# allwinner_d1_unofficial register map
File version: 0.1
Registers are 32-bit, read-write, reset 0x0 unless marked. A register's access mark holds for its fields unless they carry their own. Offsets are from the block's base; [hi:lo] are bit positions; {n}, {i} and the like mark numbered series; 'fields as' and 'values as' point back to an identical list.

## CCU — Clock Controller Unit
Base 0x02001000
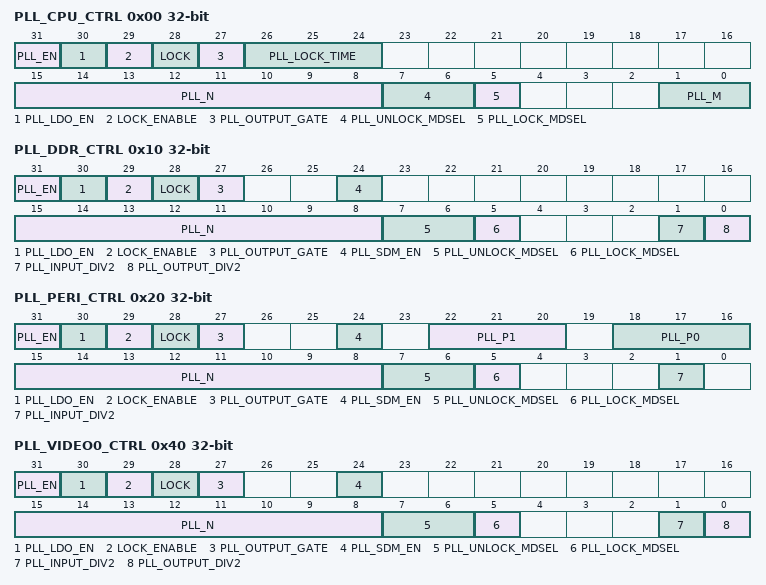
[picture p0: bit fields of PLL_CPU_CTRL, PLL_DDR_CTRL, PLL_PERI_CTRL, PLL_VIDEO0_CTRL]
0x00 PLL_CPU_CTRL — PLL_CPU Control Register
  [31] PLL_EN — PLL Enable
    0=disable; 1=enable
  [30] PLL_LDO_EN — LDO Enable
    0=disable; 1=enable
  [29] LOCK_ENABLE
    0=disable; 1=enable
  [28] LOCK ro — PLL Lock Status
    0=unlocked; 1=locked
  [27] PLL_OUTPUT_GATE — PLL Output Gating Enable
    0=disable; 1=enable
  [26:24] PLL_LOCK_TIME
  [15:8] PLL_N
  [7:6] PLL_UNLOCK_MDSEL — PLL Unlock Level
    0=CC_21_29; 1=CC_22_28; 0b1x=CC_20_30
  [5] PLL_LOCK_MDSEL — PLL Lock Level
    0=CC_24_26; 1=CC_23_27
  [1:0] PLL_M
0x10 PLL_DDR_CTRL — PLL_DDR Control Register
  [31] PLL_EN — PLL Enable
    0=disable; 1=enable
  [30] PLL_LDO_EN — LDO Enable
    0=disable; 1=enable
  [29] LOCK_ENABLE
    0=disable; 1=enable
  [28] LOCK ro — PLL Lock Status
    0=unlocked; 1=locked
  [27] PLL_OUTPUT_GATE — PLL Output Gating Enable
    0=disable; 1=enable
  [24] PLL_SDM_EN — PLL SDM Enable
    0=disable; 1=enable
  [15:8] PLL_N
  [7:6] PLL_UNLOCK_MDSEL — PLL Unlock Level
    0=CC_21_29; 1=CC_22_28; 0b1x=CC_20_30
  [5] PLL_LOCK_MDSEL — PLL Lock Level
    0=CC_24_26; 1=CC_23_27
  [1] PLL_INPUT_DIV2 — PLL Input Div M1
  [0] PLL_OUTPUT_DIV2 — PLL Output Div M0
0x20 PLL_PERI_CTRL — PLL_PERI Control Register
  [31] PLL_EN — PLL Enable
    0=disable; 1=enable
  [30] PLL_LDO_EN — LDO Enable
    0=disable; 1=enable
  [29] LOCK_ENABLE
    0=disable; 1=enable
  [28] LOCK ro — PLL Lock Status
    0=unlocked; 1=locked
  [27] PLL_OUTPUT_GATE — PLL Output Gating Enable
    0=disable; 1=enable
  [24] PLL_SDM_EN — PLL SDM Enable
    0=disable; 1=enable
  [22:20] PLL_P1 — PLL Output Div P1
  [18:16] PLL_P0 — PLL Output Div P0
  [15:8] PLL_N
  [7:6] PLL_UNLOCK_MDSEL — PLL Unlock Level
    0=CC_21_29; 1=CC_22_28; 0b1x=CC_20_30
  [5] PLL_LOCK_MDSEL — PLL Lock Level
    0=CC_24_26; 1=CC_23_27
  [1] PLL_INPUT_DIV2 — PLL Input Div M
0x40 PLL_VIDEO0_CTRL — PLL_VIDEO0 Control Register
  [31] PLL_EN — PLL Enable
    0=disable; 1=enable
  [30] PLL_LDO_EN — LDO Enable
    0=disable; 1=enable
  [29] LOCK_ENABLE
    0=disable; 1=enable
  [28] LOCK ro — PLL Lock Status
    0=unlocked; 1=locked
  [27] PLL_OUTPUT_GATE — PLL Output Gating Enable
    0=disable; 1=enable
  [24] PLL_SDM_EN — PLL SDM Enable
    0=disable; 1=enable
  [15:8] PLL_N
  [7:6] PLL_UNLOCK_MDSEL — PLL Unlock Level
    0=CC_21_29; 1=CC_22_28; 0b1x=CC_20_30
  [5] PLL_LOCK_MDSEL — PLL Lock Level
    0=CC_24_26; 1=CC_23_27
  [1] PLL_INPUT_DIV2 — PLL Input Div M
  [0] PLL_OUTPUT_DIV2 — PLL Output Div D
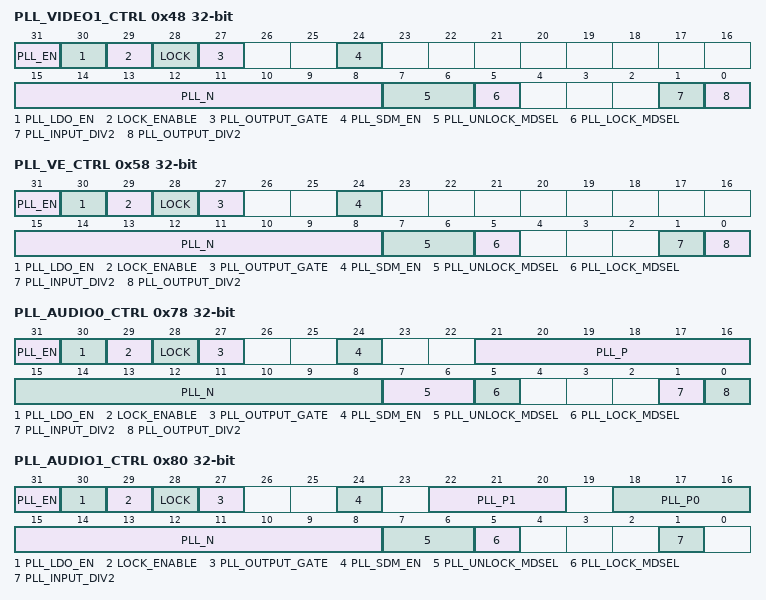
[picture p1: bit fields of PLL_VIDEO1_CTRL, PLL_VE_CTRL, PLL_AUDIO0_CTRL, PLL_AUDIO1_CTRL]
0x48 PLL_VIDEO1_CTRL — PLL_VIDEO1 Control Register
  fields as PLL_VIDEO0_CTRL
0x58 PLL_VE_CTRL — PLL_VE Control Register
  fields as PLL_DDR_CTRL
0x78 PLL_AUDIO0_CTRL — PLL_AUDIO0 Control Register
  [31] PLL_EN — PLL Enable
    0=disable; 1=enable
  [30] PLL_LDO_EN — LDO Enable
    0=disable; 1=enable
  [29] LOCK_ENABLE
    0=disable; 1=enable
  [28] LOCK ro — PLL Lock Status
    0=unlocked; 1=locked
  [27] PLL_OUTPUT_GATE — PLL Output Gating Enable
    0=disable; 1=enable
  [24] PLL_SDM_EN — PLL SDM Enable
    0=disable; 1=enable
  [21:16] PLL_P — PLL Post-div P
  [15:8] PLL_N
  [7:6] PLL_UNLOCK_MDSEL — PLL Unlock Level
    0=CC_21_29; 1=CC_22_28; 0b1x=CC_20_30
  [5] PLL_LOCK_MDSEL — PLL Lock Level
    0=CC_24_26; 1=CC_23_27
  [1] PLL_INPUT_DIV2 — PLL Input Div M1
  [0] PLL_OUTPUT_DIV2 — PLL Output Div M0
0x80 PLL_AUDIO1_CTRL — PLL_AUDIO1 Control Register
  fields as PLL_PERI_CTRL
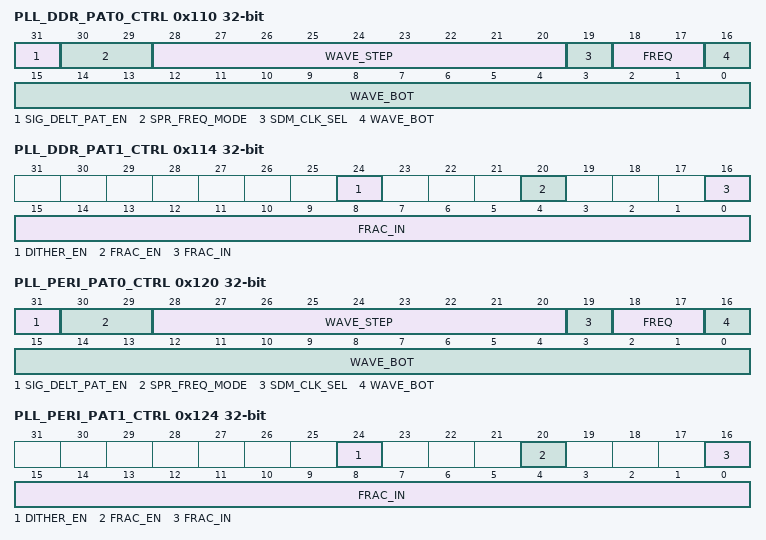
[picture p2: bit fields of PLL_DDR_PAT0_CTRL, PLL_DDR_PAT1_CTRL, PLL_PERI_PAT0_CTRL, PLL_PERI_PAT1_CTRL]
0x110 PLL_DDR_PAT0_CTRL — PLL_DDR Pattern0 Control Register
  [31] SIG_DELT_PAT_EN — Sigma-Delta Pattern Enable
  [30:29] SPR_FREQ_MODE — Spread Frequency Mode
    0=DC0; 1=DC1; 2=Triangular_1; 3=Triangular_n
  [28:20] WAVE_STEP
  [19] SDM_CLK_SEL — SDM Clock Select
    0=F_24_M; 1=F_12_M
  [18:17] FREQ — Frequency
    0=F_31_5_k; 1=F_32_k; 2=F_32_5_k; 3=F_33_k
  [16:0] WAVE_BOT — Wave Bottom
0x114 PLL_DDR_PAT1_CTRL — PLL_DDR Pattern1 Control Register
  [24] DITHER_EN — Dither Enable
  [20] FRAC_EN — Fraction Enable
  [16:0] FRAC_IN — Fraction In
0x120 PLL_PERI_PAT0_CTRL — PLL_PERI Pattern0 Control Register
  fields as PLL_DDR_PAT0_CTRL
0x124 PLL_PERI_PAT1_CTRL — PLL_PERI Pattern1 Control Register
  fields as PLL_DDR_PAT1_CTRL
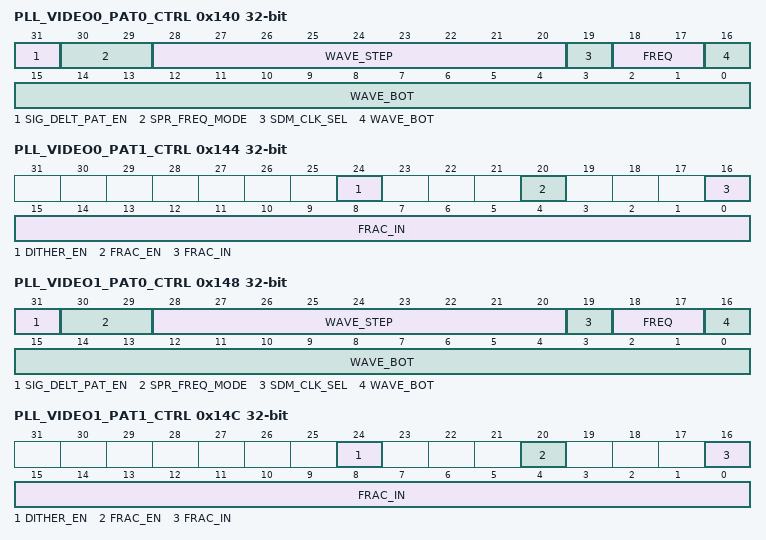
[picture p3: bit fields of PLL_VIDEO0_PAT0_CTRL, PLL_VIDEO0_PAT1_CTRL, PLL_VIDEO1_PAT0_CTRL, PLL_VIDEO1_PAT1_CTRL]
0x140 PLL_VIDEO0_PAT0_CTRL — PLL_VIDEO0 Pattern0 Control Register
  fields as PLL_DDR_PAT0_CTRL
0x144 PLL_VIDEO0_PAT1_CTRL — PLL_VIDEO0 Pattern1 Control Register
  fields as PLL_DDR_PAT1_CTRL
0x148 PLL_VIDEO1_PAT0_CTRL — PLL_VIDEO1 Pattern0 Control Register
  fields as PLL_DDR_PAT0_CTRL
0x14C PLL_VIDEO1_PAT1_CTRL — PLL_VIDEO1 Pattern1 Control Register
  fields as PLL_DDR_PAT1_CTRL
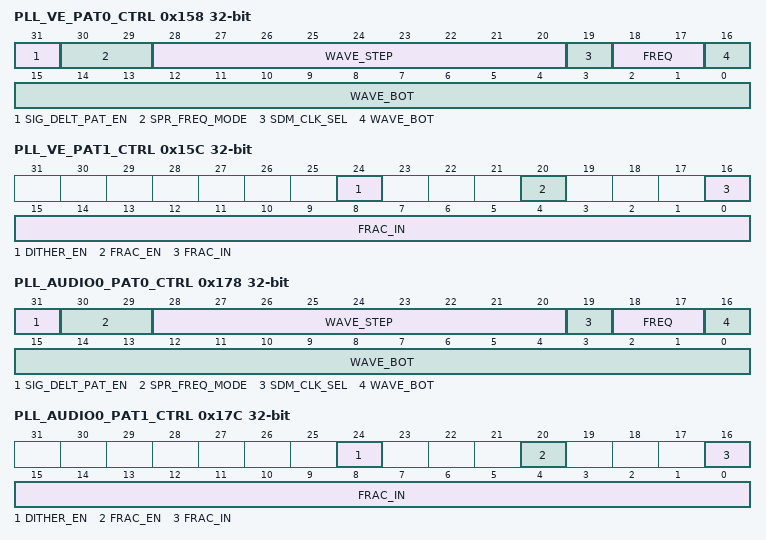
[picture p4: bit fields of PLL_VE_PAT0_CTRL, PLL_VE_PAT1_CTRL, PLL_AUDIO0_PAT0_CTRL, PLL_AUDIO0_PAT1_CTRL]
0x158 PLL_VE_PAT0_CTRL — PLL_VE Pattern0 Control Register
  fields as PLL_DDR_PAT0_CTRL
0x15C PLL_VE_PAT1_CTRL — PLL_VE Pattern1 Control Register
  fields as PLL_DDR_PAT1_CTRL
0x178 PLL_AUDIO0_PAT0_CTRL — PLL_AUDIO0 Pattern0 Control Register
  fields as PLL_DDR_PAT0_CTRL
0x17C PLL_AUDIO0_PAT1_CTRL — PLL_AUDIO0 Pattern1 Control Register
  fields as PLL_DDR_PAT1_CTRL
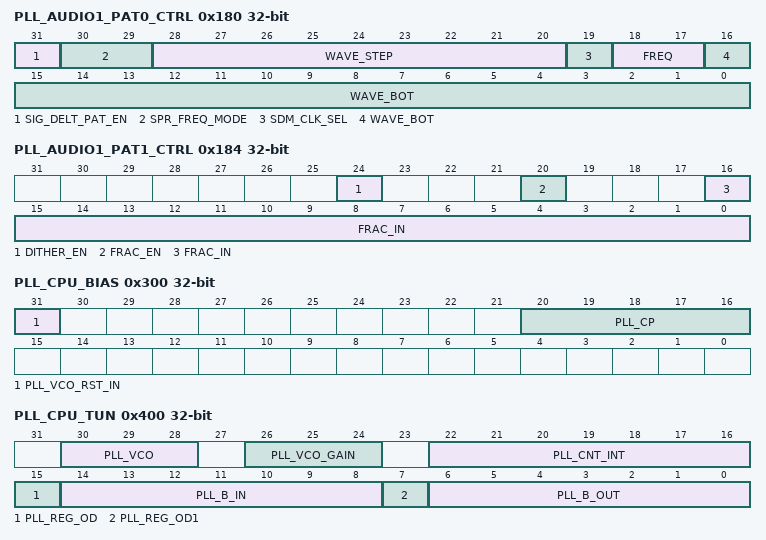
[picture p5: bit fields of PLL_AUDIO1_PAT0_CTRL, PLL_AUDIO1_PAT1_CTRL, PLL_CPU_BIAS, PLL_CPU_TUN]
0x180 PLL_AUDIO1_PAT0_CTRL — PLL_AUDIO1 Pattern0 Control Register
  fields as PLL_DDR_PAT0_CTRL
0x184 PLL_AUDIO1_PAT1_CTRL — PLL_AUDIO1 Pattern1 Control Register
  fields as PLL_DDR_PAT1_CTRL
0x300 PLL_CPU_BIAS
  [31] PLL_VCO_RST_IN — VCO reset in
  [20:16] PLL_CP — PLL current bias control
0x310 PLL_DDR_BIAS
  [20:16] PLL_CP — PLL current bias control
0x320 PLL_PERI_BIAS
  [20:16] PLL_CP — PLL current bias control
0x340 PLL_VIDEO0_BIAS
  [20:16] PLL_CP — PLL current bias control
0x348 PLL_VIDEO1_BIAS
  [20:16] PLL_CP — PLL current bias control
0x358 PLL_VE_BIAS
  [20:16] PLL_CP — PLL current bias control
0x378 PLL_AUDIO0_BIAS
  [20:16] PLL_CP — PLL current bias control
0x380 PLL_AUDIO1_BIAS
  [20:16] PLL_CP — PLL current bias control
0x400 PLL_CPU_TUN — PLL_CPU Tuning Register
  [30:28] PLL_VCO — VCO range control
  [26:24] PLL_VCO_GAIN — KVCO gain control
  [22:16] PLL_CNT_INT — Counter initial control
  [15] PLL_REG_OD — PLL-REG-OD0 for verify
  [14:8] PLL_B_IN — PLL-B-IN [6:0] for verify
  [7] PLL_REG_OD1 — PLL-REG-OD1 for verify
  [6:0] PLL_B_OUT ro — PLL-B-OUT [6:0] for verify
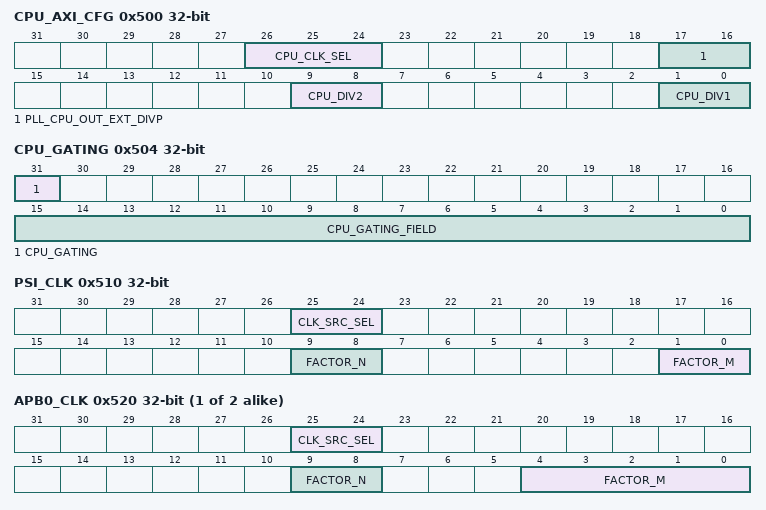
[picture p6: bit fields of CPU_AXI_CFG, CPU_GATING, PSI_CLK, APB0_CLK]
0x500 CPU_AXI_CFG — CPU_AXI Configuration Register
  [26:24] CPU_CLK_SEL — Clock Source Select
    0=HOSC; 1=CLK32K; 2=CLK16M_RC; 3=PLL_CPU_P; 4=PLL_PERI_1X; 5=PLL_PERI_2X; 6=PLL_PERI_800M
  [17:16] PLL_CPU_OUT_EXT_DIVP — PLL Output External Divider P
    0=P1; 1=P2; 2=P4
  [9:8] CPU_DIV2 — Factor N
  [1:0] CPU_DIV1 — Factor M
0x504 CPU_GATING — CPU_GATING Configuration Register
  [31] CPU_GATING — Gating Special Clock
    0=OFF; 1=ON
  [15:0] CPU_GATING_FIELD
0x510 PSI_CLK — PSI Clock Register
  [25:24] CLK_SRC_SEL — Clock Source Select
    0=HOSC; 1=CLK32K; 2=CLK16M_RC; 3=PLL_PERI_1X
  [9:8] FACTOR_N
    0=N1; 1=N2; 2=N4; 3=N8
  [1:0] FACTOR_M
{0x520+4i} APB{i}_CLK (i=0..1) — APB Clock Register
  [25:24] CLK_SRC_SEL — Clock Source Select
    0=HOSC; 1=CLK32K; 2=PSI_CLK; 3=PLL_PERI_1X
  [9:8] FACTOR_N
    0=N1; 1=N2; 2=N4; 3=N8
  [4:0] FACTOR_M
0x540 MBUS_CLK — MBUS Clock Register
  [30] MBUS_RST — MBUS Reset
    0=Assert; 1=Deassert
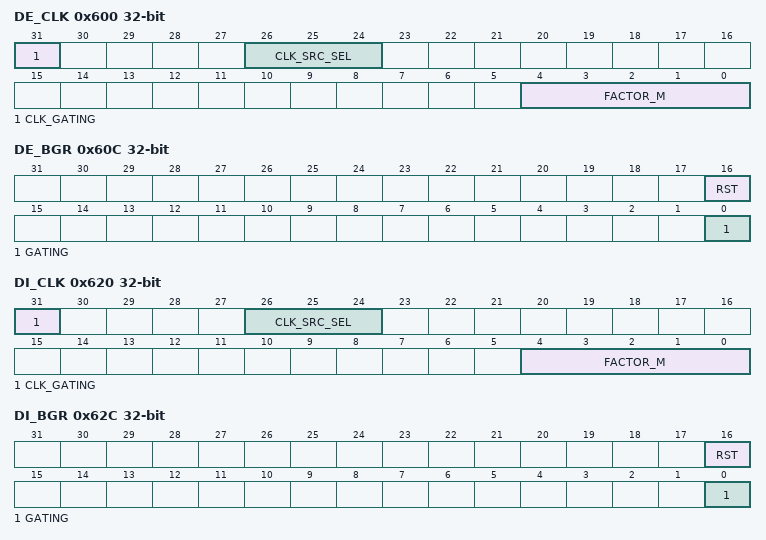
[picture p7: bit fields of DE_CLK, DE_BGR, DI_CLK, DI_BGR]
0x600 DE_CLK — DE Clock Register
  [31] CLK_GATING — Gating Clock
    0=OFF; 1=ON
  [26:24] CLK_SRC_SEL — Clock Source Select
    0=PLL_PERI_2X; 1=PLL_VIDEO0_4X; 2=PLL_VIDEO1_4X; 3=PLL_AUDIO1_DIV2
  [4:0] FACTOR_M
0x60C DE_BGR — DE Bus Gating Reset Register
  [16] RST — Reset
    0=Assert; 1=Deassert
  [0] GATING — Gating Clock
    0=Mask; 1=Pass
0x620 DI_CLK — DI Clock Register
  fields as DE_CLK
0x62C DI_BGR — DI Bus Gating Reset Register
  fields as DE_BGR
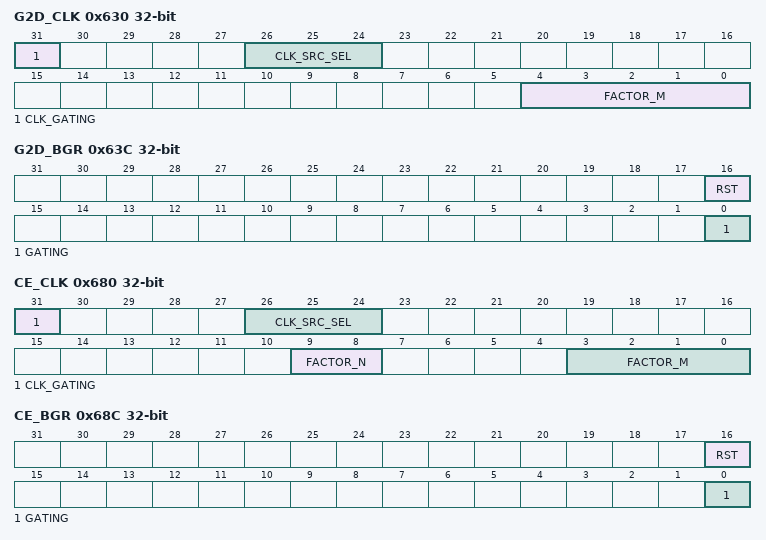
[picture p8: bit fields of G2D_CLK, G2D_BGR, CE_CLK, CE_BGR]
0x630 G2D_CLK — G2D Clock Register
  fields as DE_CLK
0x63C G2D_BGR — G2D Bus Gating Reset Register
  fields as DE_BGR
0x680 CE_CLK — CE Clock Register
  [31] CLK_GATING — Gating Clock
    0=OFF; 1=ON
  [26:24] CLK_SRC_SEL — Clock Source Select
    0=HOSC; 1=PLL_PERI_2X; 2=PLL_PERI_1X
  [9:8] FACTOR_N
    0=N1; 1=N2; 2=N4; 3=N8
  [3:0] FACTOR_M
0x68C CE_BGR — CE Bus Gating Reset Register
  fields as DE_BGR
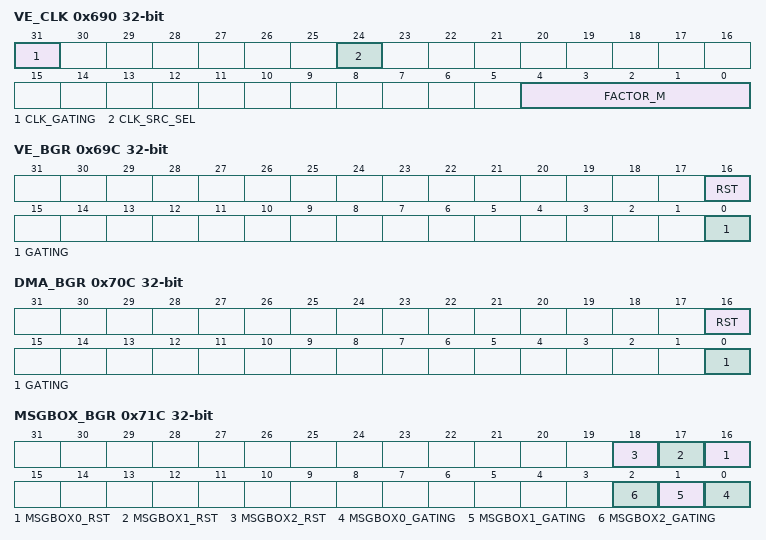
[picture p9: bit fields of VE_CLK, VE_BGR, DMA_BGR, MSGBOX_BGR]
0x690 VE_CLK — VE Clock Register
  [31] CLK_GATING — Gating Clock
    0=OFF; 1=ON
  [24] CLK_SRC_SEL — Clock Source Select
    0=VEPLL; 1=PLL_PERI_2X
  [4:0] FACTOR_M
0x69C VE_BGR — VE Bus Gating Reset Register
  fields as DE_BGR
0x70C DMA_BGR — DMA Bus Gating Reset Register
  fields as DE_BGR
0x71C MSGBOX_BGR — MSGBOX Bus Gating Reset Register
  [n+16] MSGBOX{n}_RST (n=0..2) — CPU, DSP, RISC-V MSGBOX Reset
    0=Assert; 1=Deassert
  [n] MSGBOX{n}_GATING (n=0..2) — Gating Clock for CPU, DSP, RISC-V MSGBOX
    0=Mask; 1=Pass
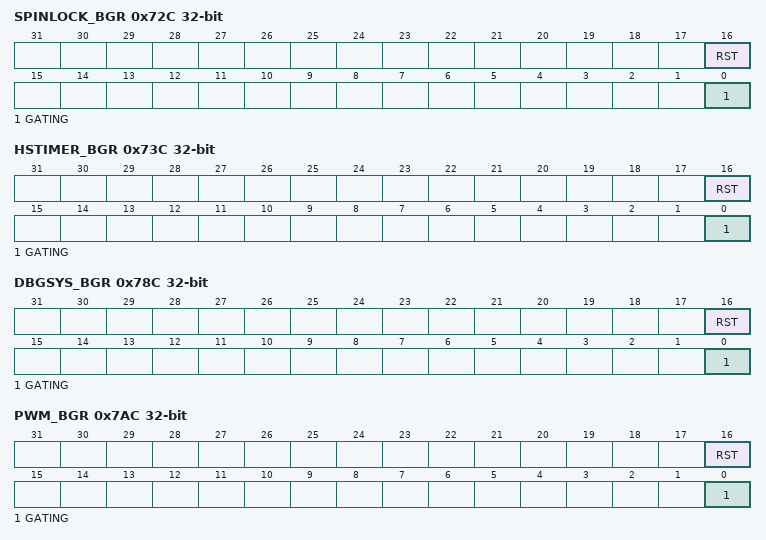
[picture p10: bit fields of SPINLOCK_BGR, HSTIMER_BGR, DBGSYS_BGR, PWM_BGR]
0x72C SPINLOCK_BGR — SPINLOCK Bus Gating Reset Register
  fields as DE_BGR
0x73C HSTIMER_BGR — HSTIMER Bus Gating Reset Register
  fields as DE_BGR
0x740 AVS_CLK — AVS Clock Register
  [31] CLK_GATING — Gating Clock
    0=OFF; 1=ON
0x78C DBGSYS_BGR — DBGSYS Bus Gating Reset Register
  fields as DE_BGR
0x7AC PWM_BGR — PWM Bus Gating Reset Register
  fields as DE_BGR
0x7BC IOMMU_BGR — IOMMU Bus Gating Reset Register
  [0] GATING — Gating Clock
    0=Mask; 1=Pass
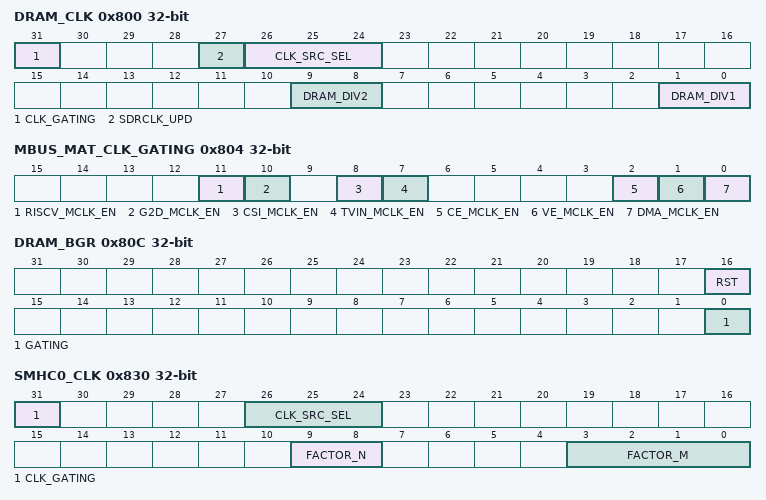
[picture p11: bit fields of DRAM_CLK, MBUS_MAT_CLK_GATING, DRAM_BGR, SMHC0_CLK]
0x800 DRAM_CLK — DRAM Clock Register
  [31] CLK_GATING — Gating Clock
    0=OFF; 1=ON
  [27] SDRCLK_UPD — SDRCLK Configuration 0 Update
    0=invalid; 1=valid
  [26:24] CLK_SRC_SEL — Clock Source Select
    0=PLL_DDR; 1=PLL_AUDIO1_DIV2; 2=PLL_PERI_2X; 3=PLL_PERI_800M
  [9:8] DRAM_DIV2 — Factor N
    0=N1; 1=N2; 2=N4; 3=N8
  [1:0] DRAM_DIV1 — Factor M
0x804 MBUS_MAT_CLK_GATING — MBUS Master Clock Gating Register
  [all] fields
    0=Mask; 1=Pass
  [11] RISCV_MCLK_EN — Gating MBUS Clock
  [10] G2D_MCLK_EN — Gating MBUS Clock
  [8] CSI_MCLK_EN — Gating MBUS Clock
  [7] TVIN_MCLK_EN — Gating MBUS Clock
  [2] CE_MCLK_EN — Gating MBUS Clock
  [1] VE_MCLK_EN — Gating MBUS Clock
  [0] DMA_MCLK_EN — Gating MBUS Clock
0x80C DRAM_BGR — DRAM Bus Gating Reset Register
  fields as DE_BGR
0x830 SMHC0_CLK — SMHC0 Clock Register
  [31] CLK_GATING — Gating Clock
    0=Off; 1=On
  [26:24] CLK_SRC_SEL — Clock Source Select
    0=HOSC; 1=PLL_PERI_1X; 2=PLL_PERI_2X; 3=PLL_AUDIO1_DIV2
  [9:8] FACTOR_N
    0=N1; 1=N2; 2=N4; 3=N8
  [3:0] FACTOR_M
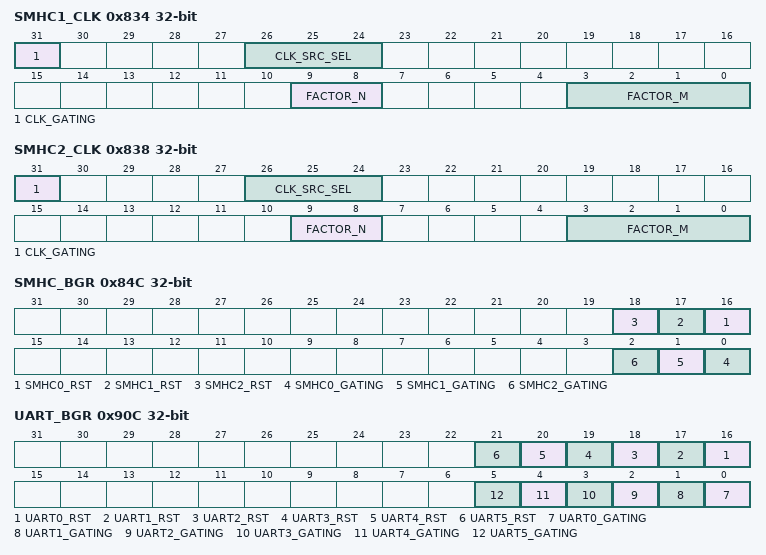
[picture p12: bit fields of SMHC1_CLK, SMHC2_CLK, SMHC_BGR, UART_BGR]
0x834 SMHC1_CLK — SMHC1 Clock Register
  fields as SMHC0_CLK
0x838 SMHC2_CLK — SMHC2 Clock Register
  [31] CLK_GATING — Gating Clock
    0=Off; 1=On
  [26:24] CLK_SRC_SEL — Clock Source Select
    0=HOSC; 1=PLL_PERI_1X; 2=PLL_PERI_2X; 3=PLL_PERI_800M; 4=PLL_AUDIO1_DIV2
  [9:8] FACTOR_N
    0=N1; 1=N2; 2=N4; 3=N8
  [3:0] FACTOR_M
0x84C SMHC_BGR — SMHC Bus Gating Reset Register
  [n+16] SMHC{n}_RST (n=0..2) — Reset
    0=Assert; 1=Deassert
  [n] SMHC{n}_GATING (n=0..2) — Gating Clock
    0=Mask; 1=Pass
0x90C UART_BGR — UART Bus Gating Reset Register
  [n+16] UART{n}_RST (n=0..5) — Reset
    0=Assert; 1=Deassert
  [n] UART{n}_GATING (n=0..5) — Gating Clock
    0=Mask; 1=Pass
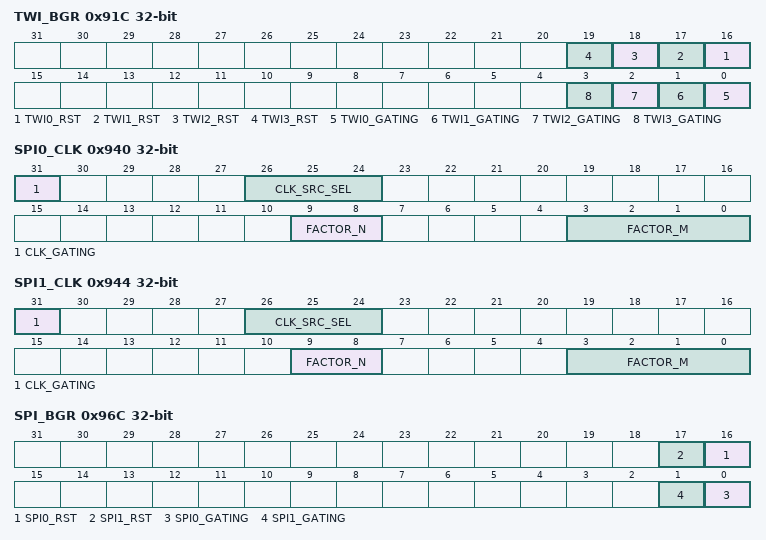
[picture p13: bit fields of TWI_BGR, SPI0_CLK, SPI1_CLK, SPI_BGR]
0x91C TWI_BGR — TWI Bus Gating Reset Register
  [n+16] TWI{n}_RST (n=0..3) — Reset
    0=Assert; 1=Deassert
  [n] TWI{n}_GATING (n=0..3) — Gating Clock
    0=Mask; 1=Pass
0x940 SPI0_CLK — SPI0 Clock Register
  [31] CLK_GATING — Gating Clock
    0=Off; 1=On
  [26:24] CLK_SRC_SEL — Clock Source Select
    0=HOSC; 1=PLL_PERI_1X; 2=PLL_PERI_2X; 3=PLL_AUDIO1_DIV2; 4=PLL_AUDIO1_DIV5
  [9:8] FACTOR_N
    0=N1; 1=N2; 2=N4; 3=N8
  [3:0] FACTOR_M
0x944 SPI1_CLK — SPI1 Clock Register
  fields as SPI0_CLK
0x96C SPI_BGR — SPI Bus Gating Reset Register
  [n+16] SPI{n}_RST (n=0..1) — Reset
    0=Assert; 1=Deassert
  [n] SPI{n}_GATING (n=0..1) — Gating Clock
    0=Mask; 1=Pass
0x970 EMAC_25M_CLK — EMAC_25M Clock Register
  [31] CLK_GATING — Gating Special Clock
    0=Off; 1=On
  [31] CLK_SRC_GATING — Gating the Source Clock of Special Clock
    0=Off; 1=On
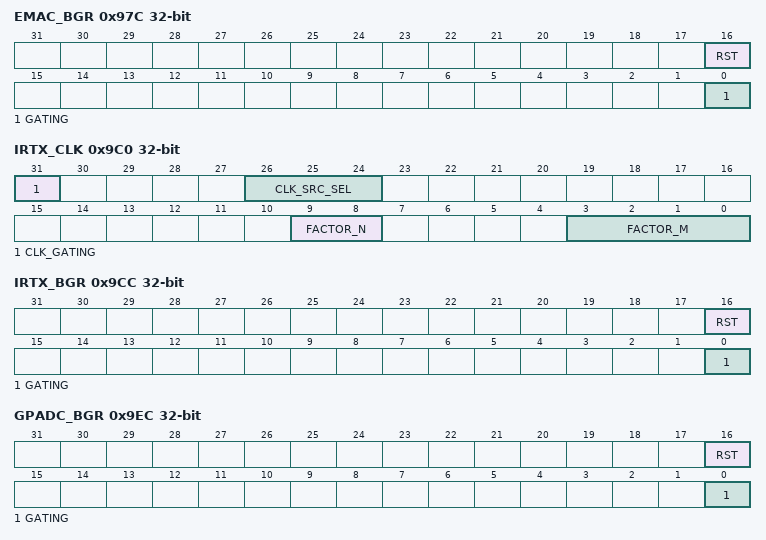
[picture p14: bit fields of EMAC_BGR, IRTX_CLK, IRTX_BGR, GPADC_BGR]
0x97C EMAC_BGR — EMAC Bus Gating Reset Register
  fields as DE_BGR
0x9C0 IRTX_CLK — IRTX Clock Register
  [31] CLK_GATING — Gating Clock
    0=Off; 1=On
  [26:24] CLK_SRC_SEL — Clock Source Select
    0=HOSC; 1=PLL_PERI_1X
  [9:8] FACTOR_N
    0=N1; 1=N2; 2=N4; 3=N8
  [3:0] FACTOR_M
0x9CC IRTX_BGR — IRTX Bus Gating Reset Register
  fields as DE_BGR
0x9EC GPADC_BGR — GPADC Bus Gating Reset Register
  fields as DE_BGR
0x9FC THS_BGR — THS Bus Gating Reset Register
  fields as DE_BGR
{0xA10+4i} I2S{i}_CLK (i=0..2) — I2S Clock Register
  [31] CLK_GATING — Gating Clock
    0=Off; 1=On
  [26:24] CLK_SRC_SEL — Clock Source Select
    0=PLL_AUDIO0_1X; 1=PLL_AUDIO0_4X; 2=PLL_AUDIO1_DIV2; 3=PLL_AUDIO1_DIV5
  [9:8] FACTOR_N
    0=N1; 1=N2; 2=N4; 3=N8
  [4:0] FACTOR_M
0xA1C I2S2_ASRC_CLK — I2S2_ASRC Clock Register
  [31] CLK_GATING — Gating Clock
    0=Off; 1=On
  [26:24] CLK_SRC_SEL — Clock Source Select
    0=PLL_AUDIO0_4X; 1=PLL_PERI_1X; 2=PLL_AUDIO1_DIV2; 3=PLL_AUDIO1_DIV5
  [9:8] FACTOR_N
    0=N1; 1=N2; 2=N4; 3=N8
  [4:0] FACTOR_M
0xA20 I2S_BGR — I2S Bus Gating Reset Register
  [n+16] I2S{n}_RST (n=0..2) — Reset
    0=Assert; 1=Deassert
  [n] I2S{n}_GATING (n=0..2) — Gating Clock
    0=Mask; 1=Pass
0xA24 OWA_TX_CLK — OWA_TX Clock Register
  fields as I2S0_CLK
0xA28 OWA_RX_CLK — OWA_RX Clock Register
  [31] CLK_GATING — Gating Clock
    0=Off; 1=On
  [26:24] CLK_SRC_SEL — Clock Source Select
    0=PLL_PERI_1X; 1=PLL_AUDIO1_DIV2; 2=PLL_AUDIO1_DIV5
  [9:8] FACTOR_N
    0=N1; 1=N2; 2=N4; 3=N8
  [4:0] FACTOR_M
0xA2C OWA_BGR — OWA Bus Gating Reset Register
  fields as DE_BGR
0xA40 DMIC_CLK — DMIC Clock Register
  fields as OWA_RX_CLK
0xA4C DMIC_BGR — DMIC Bus Gating Reset Register
  fields as DE_BGR
0xA50 AUDIO_CODEC_DAC_CLK — AUDIO_CODEC_DAC Clock Register
  [31] CLK_GATING — Gating Clock
    0=Off; 1=On
  [26:24] CLK_SRC_SEL — Clock Source Select
    0=PLL_AUDIO0_1X; 1=PLL_AUDIO1_DIV2; 2=PLL_AUDIO1_DIV5
  [9:8] FACTOR_N
    0=N1; 1=N2; 2=N4; 3=N8
  [4:0] FACTOR_M
0xA54 AUDIO_CODEC_ADC_CLK — AUDIO_CODEC_ADC Clock Register
  fields as AUDIO_CODEC_DAC_CLK
0xA5C AUDIO_CODEC_BGR — AUDIO_CODEC Bus Gating Reset Register
  fields as DE_BGR
0xA70 USB0_CLK — USB0 Clock Register
  [31] CLKEN — Gating Special Clock
    0=Off; 1=On
  [30] RSTN — PHY Reset
    0=Assert; 1=Deassert
  [25:24] CLK12M_SEL — OHCI 12M Source Select
    0=DIV_48M; 1=DIV_24M; 2=RTC_32K
0xA74 USB1_CLK — USB1 Clock Register
  fields as USB0_CLK
0xA8C USB_BGR — USB Bus Gating Reset Register
  [24] USBOTG0_RST — USBOTG0 Reset
    0=Assert; 1=Deassert
  [n+20] USBEHCI{n}_RST (n=0..1) — USBEHCI Reset
    0=Assert; 1=Deassert
  [n+16] USBOHCI{n}_RST (n=0..1) — USBOHCI Reset
    0=Assert; 1=Deassert
  [8] USBOTG0_GATING — USBOTG0 Gating Clock
    0=Mask; 1=Pass
  [n+4] USBEHCI{n}_GATING (n=0..1) — USBEHCI Gating Clock
    0=Mask; 1=Pass
  [n] USBOHCI{n}_GATING (n=0..1) — USBOHCI Gating Clock
    0=Mask; 1=Pass
0xA9C LRADC_BGR — LRADC Bus Gating Reset Register
  fields as DE_BGR
0xABC DPSS_TOP_BGR — DPSS_TOP Bus Gating Reset Register
  fields as DE_BGR
0xB24 DSI_CLK — DSI Clock Register
  [31] CLK_GATING — Gating Clock
    0=Off; 1=On
  [26:24] CLK_SRC_SEL — Clock Source Select
    0=HOSC; 1=PLL_PERI_1X; 2=PLL_VIDEO0_2X; 3=PLL_VIDEO1_2X; 4=PLL_AUDIO1_DIV2
  [3:0] FACTOR_M
0xB4C DSI_BGR — DSI Bus Gating Reset Register
  fields as DE_BGR
0xB60 TCONLCD_CLK — TCONLCD Clock Register
  [31] CLK_GATING — Gating Clock
    0=Off; 1=On
  [26:24] CLK_SRC_SEL — Clock Source Select
    0=PLL_VIDEO0_1X; 1=PLL_VIDEO0_4X; 2=PLL_VIDEO1_1X; 3=PLL_VIDEO1_4X; 4=PLL_PERI_2X; 5=PLL_AUDIO1_DIV2
  [9:8] FACTOR_N
    0=N1; 1=N2; 2=N4; 3=N8
  [3:0] FACTOR_M
0xB7C TCONLCD_BGR — TCONLCD Bus Gating Reset Register
  fields as DE_BGR
0xB80 TCONTV_CLK — TCONTV Clock Register
  fields as TCONLCD_CLK
0xB9C TCONTV_BGR — TCONTV Bus Gating Reset Register
  fields as DE_BGR
0xBAC LVDS_BGR — LVDS Bus Gating Reset Register
  [16] RST — Reset
    0=Assert; 1=Deassert
0xBB0 TVE_CLK — TVE Clock Register
  fields as TCONLCD_CLK
0xBBC TVE_BGR — TVE Bus Gating Reset Register
  [17] RST — Reset
    0=Assert; 1=Deassert
  [16] TOP_RST — Reset
    0=Assert; 1=Deassert
  [1] GATING — Gating Clock
    0=Mask; 1=Pass
  [0] TOP_GATING — Gating Clock
    0=Mask; 1=Pass
0xBC0 TVD_CLK — TVD Clock Register
  [31] CLK_GATING — Gating Clock
    0=Off; 1=On
  [26:24] CLK_SRC_SEL — Clock Source Select
    0=HOSC; 1=PLL_VIDEO0_1X; 2=PLL_VIDEO1_1X; 3=PLL_PERI_1X
  [4:0] FACTOR_M
0xBDC TVD_BGR — TVD Bus Gating Reset Register
  fields as TVE_BGR
0xBF0 LEDC_CLK — LEDC Clock Register
  fields as IRTX_CLK
0xBFC LEDC_BGR — LEDC Bus Gating Reset Register
  fields as DE_BGR
0xC04 CSI_CLK — CSI Clock Register
  [31] CLK_GATING — Gating Clock
    0=Off; 1=On
  [26:24] CLK_SRC_SEL — Clock Source Select
    0=PLL_PERI_2X; 1=PLL_VIDEO0_2X; 2=PLL_VIDEO1_2X
  [3:0] FACTOR_M
0xC08 CSI_MASTER_CLK — CSI Master Clock Register
  [31] CLK_GATING — Gating Clock
    0=Off; 1=On
  [26:24] CLK_SRC_SEL — Clock Source Select
    0=HOSC; 1=PLL_PERI_1X; 2=PLL_VIDEO0_1X; 3=PLL_VIDEO1_1X; 4=PLL_AUDIO1_DIV2; 5=PLL_AUDIO1_DIV5
  [4:0] FACTOR_M
0xC1C CSI_BGR — CSI Bus Gating Reset Register
  fields as DE_BGR
0xC50 TPADC_CLK — TPADC Clock Register
  [31] CLK_GATING — Gating Clock
    0=Off; 1=On
  [26:24] CLK_SRC_SEL — Clock Source Select
    0=HOSC; 1=PLL_AUDIO0_1X
0xC5C TPADC_BGR — TPADC Bus Gating Reset Register
  fields as DE_BGR
0xC70 DSP_CLK — DSP Clock Register
  [31] CLK_GATING — Gating Clock
    0=Off; 1=On
  [26:24] CLK_SRC_SEL — Clock Source Select
    0=HOSC; 1=CLK32K; 2=CLK16M_RC; 3=PLL_PERI_2X; 4=PLL_AUDIO1_DIV2
  [4:0] FACTOR_M
0xC7C DSP_BGR — DSP Bus Gating Reset Register
  [18] DBG_RST — Reset
    0=Assert; 1=Deassert
  [17] CFG_RST — Reset
    0=Assert; 1=Deassert
  [16] RST — Reset
    0=Assert; 1=Deassert
  [1] CFG_GATING — Gating Clock
    0=Mask; 1=Pass
0xD00 RISCV_CLK — RISC-V Clock Register
  [26:24] CLK_SRC_SEL — Clock Source Select
    0=HOSC; 1=CLK32K; 2=CLK16M_RC; 3=PLL_PERI_800M; 4=PLL_PERI_1X; 5=PLL_CPU; 6=PLL_AUDIO1_DIV2
  [9:8] AXI_DIV_CFG — Factor N
  [4:0] DIV_CFG — Factor M
0xD04 RISCV_GATING — RISC-V GATING Configuration Register
  [31] GATING — Gating Clock
    0=Mask; 1=Pass
  [15:0] GATING_FIELD
0xD0C RISCV_CFG_BGR — RISC-V_CFG Bus Gating Reset Register
  fields as DE_BGR
0xF04 PLL_LOCK_DBG_CTRL — PLL Lock Debug Control Register
  [31] PLL_LOCK_FLAG_EN — Debug Enable
    0=Disable; 1=Enable
  [22:20] CLK_SRC_SEL — Clock Source Select
    0=PLL_CPUX; 1=PLL_DDR; 2=PLL_PERI_2X; 3=PLL_VIDEO0_4X; 4=PLL_VIDEO1_4X; 5=PLL_VE; 6=PLL_AUDIO0; 7=PLL_AUDIO1
0xF08 FRE_DET_CTRL — Frequency Detect Control Register
  [31] ERROR_FLAG write-0-clears
    0=W0C; 1=Error
  [8:4] DET_TIME — Detect Time
  [1] FRE_DET_IRQ_EN — Frequence Detect IRQ Enable
    0=Disable; 1=Enable
  [0] FRE_DET_FUN_EN — Frequence Detect Function Enable
    0=Disable; 1=Enable
0xF0C FRE_UP_LIM — Frequency Up Limit Register
0xF10 FRE_DOWN_LIM — Frequency Down Limit Register
0xF30 CCU_FAN_GATE — CCU FANOUT CLOCK GATE Register
  [all] fields
    0=OFF; 1=ON
  [4] CLK32K_EN — Gating for CLK32K
  [3] CLK25M_EN — Gating for CLK25M
  [2] CLK16M_EN — Gating for CLK16M
  [1] CLK12M_EN — Gating for CLK12M
  [0] CLK24M_EN — Gating for CLK24M
0xF34 CLK27M_FAN — CLK27M FANOUT Register
  [31] GATING — Gating for CLK27M
    0=OFF; 1=ON
  [25:24] CLK_SRC_SEL — Clock Source Select
    0=PLL_VIDEO0_1X; 1=PLL_VIDEO1_1X
  [9:8] DIV1 — Factor N
  [4:0] DIV0 — Factor M
0xF38 PCLK_FAN — PCLK FANOUT Register
  [31] GATING — Gating for PCLK
    0=OFF; 1=ON
  [4:0] DIV — Factor M
0xF3C CCU_FAN — CCU FANOUT Register
  [n+21] CLK_FANOUT{n}_EN (n=0..2) — Gating for CLK_FANOUT
    0=OFF; 1=ON
  [3n+2:3n] CLK_FANOUT{n}_SEL (n=0..2)
    0=CLK32K; 1=CLK12M; 2=CLK16M; 3=CLK24M; 4=CLK25M; 5=CLK27M; 6=PCLK
